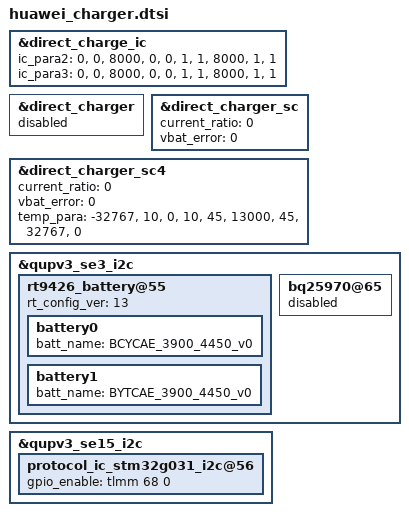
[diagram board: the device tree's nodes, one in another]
&direct_charge_ic {
	ic_para2 =
		"0", "0", "8000", "0", "0",
		"1", "1", "8000", "1", "1";
	ic_para3 =
		"0", "0", "8000", "0", "0",
		"1", "1", "8000", "1", "1";
};

&direct_charger {
	status = "disabled";
};

&direct_charger_sc {
	current_ratio = "0";
	vbat_error = "0";
};

&direct_charger_sc4 {
	current_ratio = "0";
	vbat_error = "0";
	temp_para =
		"-32767", "10", "0",
		"10", "45", "13000",
		"45", "32767", "0";
};

&qupv3_se3_i2c {
	rt9426_battery@55{
		rt_config_ver = <13>;
		battery0{
			batt_name = "BCYCAE_3900_4450_v0";
			#include "../../../huawei_charger/rt9426_0P5mohm_BITCAE_3900mAh_4V45_BT216.dtsi"
		};
		battery1{
                        batt_name = "BYTCAE_3900_4450_v0";
                        #include "../../../huawei_charger/rt9426_0P5mohm_BITCAE_3900mAh_4V45_BT216.dtsi"
                };
	};
	bq25970@65 {
		status = "disabled";
	};
};

&qupv3_se15_i2c {
	protocol_ic_stm32g031_i2c@56 {
		gpio_enable = <&tlmm 68 0>;
	};
};
